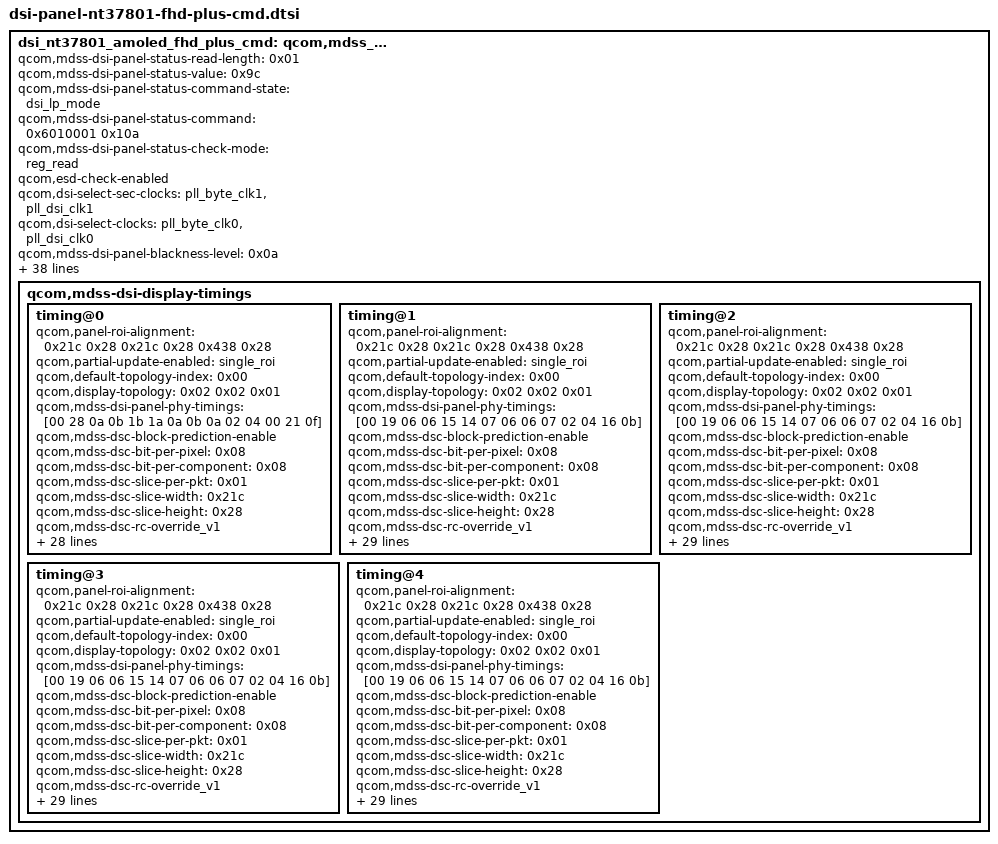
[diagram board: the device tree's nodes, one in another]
// SPDX-License-Identifier: BSD-3-Clause
/*
 * Copyright (c) 2023-2024 Qualcomm Innovation Center, Inc. All rights reserved.
 * Copyright (c) 2025 The LineageOS Project
 */

dsi_nt37801_amoled_fhd_plus_cmd: qcom,mdss_dsi_nt37801_fhd_plus_cmd {
	qcom,mdss-dsi-panel-status-read-length = <0x01>;
	qcom,mdss-dsi-panel-status-value = <0x9c>;
	qcom,mdss-dsi-panel-status-command-state = "dsi_lp_mode";
	qcom,mdss-dsi-panel-status-command = <0x6010001 0x10a>;
	qcom,mdss-dsi-panel-status-check-mode = "reg_read";
	qcom,esd-check-enabled;
	qcom,dsi-select-sec-clocks = "pll_byte_clk1", "pll_dsi_clk1";
	qcom,dsi-select-clocks = "pll_byte_clk0", "pll_dsi_clk0";
	qcom,mdss-dsi-panel-blackness-level = <0x0a>;
	qcom,mdss-dsi-panel-peak-brightness = <0xc65d40>;
	qcom,mdss-dsi-panel-hdr-color-primaries = <0x3b2e 0x3d86 0x85ca 0x3d54 0x2fda 0x8bd8 0x1a5e 0x9f6>;
	qcom,mdss-dsi-panel-hdr-enabled;
	qcom,spr-pack-type = "pentile";
	qcom,mdss-dsi-te-using-te-pin;
	qcom,mdss-dsi-te-check-enable;
	qcom,mdss-dsi-te-dcs-command = <0x01>;
	qcom,mdss-dsi-wr-mem-continue = <0x3c>;
	qcom,mdss-dsi-wr-mem-start = <0x2c>;
	qcom,mdss-dsi-te-pin-select = <0x01>;
	qcom,mdss-dsi-reset-sequence = <0x01 0x0a 0x00 0x0a 0x01 0x0a>;
	qcom,mdss-dsi-mdp-trigger = "none";
	qcom,mdss-dsi-dma-trigger = "trigger_sw";
	qcom,mdss-dsi-lane-3-state;
	qcom,mdss-dsi-lane-2-state;
	qcom,mdss-dsi-lane-1-state;
	qcom,mdss-dsi-lane-0-state;
	qcom,mdss-dsi-bllp-power-mode;
	qcom,mdss-dsi-bllp-eof-power-mode;
	qcom,mdss-dsi-lane-map = "lane_map_0123";
	qcom,mdss-dsi-traffic-mode = "non_burst_sync_event";
	qcom,dsi-sec-phy-num = <0x01>;
	qcom,dsi-sec-ctrl-num = <0x01>;
	qcom,dsi-phy-num = <0x00>;
	qcom,dsi-ctrl-num = <0x00>;
	qcom,mdss-dsi-border-color = <0x00>;
	qcom,mdss-dsi-underflow-color = <0xff>;
	qcom,mdss-dsi-color-order = "rgb_swap_rgb";
	qcom,mdss-dsi-bpp = <0x18>;
	qcom,mdss-dsi-stream = <0x00>;
	qcom,mdss-dsi-virtual-channel-id = <0x00>;
	qcom,mdss-dsi-panel-physical-type = "oled";
	qcom,mdss-dsi-panel-type = "dsi_cmd_mode";
	qcom,mdss-dsi-panel-name = "nt37801 amoled fhd plus cmd mode dsi csot panel with DSC";

	qcom,mdss-dsi-display-timings {

		timing@0 {
			qcom,panel-roi-alignment = <0x21c 0x28 0x21c 0x28 0x438 0x28>;
			qcom,partial-update-enabled = "single_roi";
			qcom,default-topology-index = <0x00>;
			qcom,display-topology = <0x02 0x02 0x01>;
			qcom,mdss-dsi-panel-phy-timings = [00 28 0a 0b 1b 1a 0a 0b 0a 02 04 00 21 0f];
			qcom,mdss-dsc-block-prediction-enable;
			qcom,mdss-dsc-bit-per-pixel = <0x08>;
			qcom,mdss-dsc-bit-per-component = <0x08>;
			qcom,mdss-dsc-slice-per-pkt = <0x01>;
			qcom,mdss-dsc-slice-width = <0x21c>;
			qcom,mdss-dsc-slice-height = <0x28>;
			qcom,mdss-dsc-rc-override_v1;
			qcom,compression-mode = "dsc";
			qcom,mdss-dsi-h-sync-pulse = <0x00>;
			qcom,mdss-dsi-timing-switch-command-state = "dsi_lp_mode";
			qcom,mdss-dsi-off-command-state = "dsi_hs_mode";
			qcom,mdss-dsi-on-command-state = "dsi_lp_mode";
			qcom,mdss-dsi-off-command = [05 01 00 00 14 00 02 28 00 05 01 00 00 78 00 02 10 00];
			qcom,mdss-dsi-on-command = [39 01 00 00 00 00 06 f0 55 aa 52 08 01 39 01 00 00 00 00 02 6f 01 39 01 00 00 00 00 04 c5 0b 0b 0b 39 01 00 00 00 00 05 ff aa 55 a5 80 39 01 00 00 00 00 02 6f 02 39 01 00 00 00 00 02 f5 10 39 01 00 00 00 00 02 6f 1b 39 01 00 00 00 00 02 f4 55 39 01 00 00 00 00 02 6f 18 39 01 00 00 00 00 02 f8 19 39 01 00 00 00 00 02 6f 0f 39 01 00 00 00 00 02 fc 00 39 01 00 00 00 00 05 2a 00 00 04 37 39 01 00 00 00 00 05 2b 00 00 09 5f 39 01 00 00 00 00 02 90 03 39 01 00 00 00 00 13 91 89 28 00 28 c2 00 02 0e 03 dd 00 07 02 77 02 8b 10 f0 39 01 00 00 00 00 05 ff aa 55 a5 81 39 01 00 00 00 00 02 6f 23 39 01 00 00 00 00 15 fb 00 01 00 11 33 33 33 55 57 d0 00 00 44 56 77 78 9a bc dd f0 39 01 00 00 00 00 13 93 89 28 00 28 d2 00 02 25 03 b6 00 07 02 ab 02 8b 10 f0 39 01 00 00 00 00 13 95 89 28 00 28 d2 00 01 c3 02 fc 00 05 02 ab 03 d1 10 f0 39 01 00 00 00 00 02 03 00 39 01 00 00 00 00 02 8f 01 39 01 00 00 00 00 02 6f 06 39 01 00 00 00 00 02 f3 dc 39 01 00 00 00 00 02 26 00 39 01 00 00 00 00 02 35 00 39 01 00 00 00 00 05 3b 00 18 00 10 39 01 00 00 00 00 02 53 20 39 01 00 00 00 00 07 51 07 ff 07 ff 0f ff 39 01 00 00 00 00 02 5a 01 39 01 00 00 00 00 02 5f 00 39 01 00 00 00 00 02 9c 01 05 01 00 00 00 00 01 2c 39 01 00 00 00 00 02 2f 00 05 01 00 00 78 00 01 11 05 01 00 00 14 00 01 29];
			qcom,mdss-dsi-timing-switch-command = [39 01 00 00 00 00 05 2a 00 00 04 37 39 01 00 00 00 00 05 2b 00 00 09 5f 39 01 00 00 00 00 02 8f 01 39 01 00 00 00 00 02 2f 00 39 01 00 00 00 00 02 26 00 39 01 00 00 00 00 06 f0 55 aa 52 08 00 39 01 00 00 00 00 06 c0 54 c0 00 21 43 39 01 00 00 00 00 06 f0 55 aa 52 08 02 39 01 00 00 00 00 02 cc 30 39 01 00 00 00 00 02 ce 01 39 01 00 00 20 00 02 cc 00];
			qcom,mdss-dsi-panel-jitter = <0x04 0x01>;
			qcom,mdss-dsi-v-bottom-border = <0x00>;
			qcom,mdss-dsi-v-top-border = <0x00>;
			qcom,mdss-dsi-h-right-border = <0x00>;
			qcom,mdss-dsi-h-left-border = <0x00>;
			qcom,mdss-dsi-v-pulse-width = <0x02>;
			qcom,mdss-dsi-v-front-porch = <0x14>;
			qcom,mdss-dsi-v-back-porch = <0x12>;
			qcom,mdss-dsi-h-sync-skew = <0x00>;
			qcom,mdss-dsi-h-pulse-width = <0x04>;
			qcom,mdss-dsi-h-back-porch = <0x14>;
			qcom,mdss-dsi-h-front-porch = <0x14>;
			qcom,mdss-dsi-panel-height = <0x960>;
			qcom,mdss-dsi-panel-width = <0x438>;
			qcom,mdss-dsi-panel-framerate = <0x78>;
			cell-index = <0x00>;
		};

		timing@1 {
			qcom,panel-roi-alignment = <0x21c 0x28 0x21c 0x28 0x438 0x28>;
			qcom,partial-update-enabled = "single_roi";
			qcom,default-topology-index = <0x00>;
			qcom,display-topology = <0x02 0x02 0x01>;
			qcom,mdss-dsi-panel-phy-timings = [00 19 06 06 15 14 07 06 06 07 02 04 16 0b];
			qcom,mdss-dsc-block-prediction-enable;
			qcom,mdss-dsc-bit-per-pixel = <0x08>;
			qcom,mdss-dsc-bit-per-component = <0x08>;
			qcom,mdss-dsc-slice-per-pkt = <0x01>;
			qcom,mdss-dsc-slice-width = <0x21c>;
			qcom,mdss-dsc-slice-height = <0x28>;
			qcom,mdss-dsc-rc-override_v1;
			qcom,compression-mode = "dsc";
			qcom,mdss-dsi-h-sync-pulse = <0x00>;
			qcom,mdss-dsi-timing-switch-command-state = "dsi_lp_mode";
			qcom,mdss-dsi-off-command-state = "dsi_hs_mode";
			qcom,mdss-dsi-on-command-state = "dsi_lp_mode";
			qcom,mdss-dsi-off-command = [05 01 00 00 14 00 02 28 00 05 01 00 00 78 00 02 10 00];
			qcom,mdss-dsi-on-command = <0x39010000 0x6f0 0x55aa5208 0x1390100 0x02 0x6f013901 0x00 0x4c50b0b 0xb390100 0x05 0xffaa55a5 0x80390100 0x02 0x6f063901 0x00 0x2f3dc39 0x1000000 0x26f02 0x39010000 0x2f5 0x10390100 0x02 0x6f1b3901 0x00 0x2f45539 0x1000000 0x26f18 0x39010000 0x2f8 0x19390100 0x02 0x6f0f3901 0x00 0x2fc0039 0x1000000 0x52a00 0x43739 0x1000000 0x52b00 0x95f39 0x1000000 0x29003 0x39010000 0x1391 0x89280028 0xc200020e 0x3dd0007 0x277028b 0x10f03901 0x00 0x5ffaa55 0xa5813901 0x00 0x26f2339 0x1000000 0x15fb00 0x1001133 0x33335557 0xd0000044 0x5677789a 0xbcddf039 0x1000000 0x23500 0x39010000 0x53b 0x180010 0x39010000 0x253 0x20390100 0x07 0x5107ff07 0xff0fff39 0x1000000 0x25a01 0x39010000 0x25f 0x390100 0x02 0x9c010501 0x00 0x12c3901 0x00 0x28f0139 0x1000000 0x22f01 0x39010000 0x226 0x1390100 0x06 0xf055aa52 0x8003901 0x00 0x6c054c0 0x244539 0x1000000 0x6f055 0xaa520802 0x39010000 0x2cc 0x30390100 0x02 0xce013901 0x2000 0x2cc0039 0x1000000 0x6f055 0xaa520801 0x39010000 0x5b2 0x5501ff03 0x5010000 0x78000111 0x5010000 0x14000129>;
			qcom,mdss-dsi-timing-switch-command = [39 01 00 00 00 00 05 2a 00 00 04 37 39 01 00 00 00 00 05 2b 00 00 09 5f 39 01 00 00 00 00 02 8f 01 39 01 00 00 00 00 02 2f 01 39 01 00 00 00 00 02 26 01 39 01 00 00 00 00 06 f0 55 aa 52 08 00 39 01 00 00 00 00 06 c0 54 c0 00 24 45 39 01 00 00 00 00 06 f0 55 aa 52 08 02 39 01 00 00 00 00 02 cc 30 39 01 00 00 00 00 02 ce 01 39 01 00 00 20 00 02 cc 00];
			qcom,mdss-dsi-panel-clockrate = <0x2887fa00>;
			qcom,mdss-dsi-panel-jitter = <0x04 0x01>;
			qcom,mdss-dsi-v-bottom-border = <0x00>;
			qcom,mdss-dsi-v-top-border = <0x00>;
			qcom,mdss-dsi-h-right-border = <0x00>;
			qcom,mdss-dsi-h-left-border = <0x00>;
			qcom,mdss-dsi-v-pulse-width = <0x02>;
			qcom,mdss-dsi-v-front-porch = <0x14>;
			qcom,mdss-dsi-v-back-porch = <0x12>;
			qcom,mdss-dsi-h-sync-skew = <0x00>;
			qcom,mdss-dsi-h-pulse-width = <0x04>;
			qcom,mdss-dsi-h-back-porch = <0x14>;
			qcom,mdss-dsi-h-front-porch = <0x14>;
			qcom,mdss-dsi-panel-height = <0x960>;
			qcom,mdss-dsi-panel-width = <0x438>;
			qcom,mdss-dsi-panel-framerate = <0x5a>;
			cell-index = <0x01>;
		};

		timing@2 {
			qcom,panel-roi-alignment = <0x21c 0x28 0x21c 0x28 0x438 0x28>;
			qcom,partial-update-enabled = "single_roi";
			qcom,default-topology-index = <0x00>;
			qcom,display-topology = <0x02 0x02 0x01>;
			qcom,mdss-dsi-panel-phy-timings = [00 19 06 06 15 14 07 06 06 07 02 04 16 0b];
			qcom,mdss-dsc-block-prediction-enable;
			qcom,mdss-dsc-bit-per-pixel = <0x08>;
			qcom,mdss-dsc-bit-per-component = <0x08>;
			qcom,mdss-dsc-slice-per-pkt = <0x01>;
			qcom,mdss-dsc-slice-width = <0x21c>;
			qcom,mdss-dsc-slice-height = <0x28>;
			qcom,mdss-dsc-rc-override_v1;
			qcom,compression-mode = "dsc";
			qcom,mdss-dsi-h-sync-pulse = <0x00>;
			qcom,mdss-dsi-timing-switch-command-state = "dsi_lp_mode";
			qcom,mdss-dsi-off-command-state = "dsi_hs_mode";
			qcom,mdss-dsi-on-command-state = "dsi_lp_mode";
			qcom,mdss-dsi-off-command = [05 01 00 00 14 00 02 28 00 05 01 00 00 78 00 02 10 00];
			qcom,mdss-dsi-on-command = [39 01 00 00 00 00 06 f0 55 aa 52 08 01 39 01 00 00 00 00 02 6f 01 39 01 00 00 00 00 04 c5 0b 0b 0b 39 01 00 00 00 00 05 ff aa 55 a5 80 39 01 00 00 00 00 02 6f 02 39 01 00 00 00 00 02 f5 10 39 01 00 00 00 00 02 6f 1b 39 01 00 00 00 00 02 f4 55 39 01 00 00 00 00 02 6f 18 39 01 00 00 00 00 02 f8 19 39 01 00 00 00 00 02 6f 0f 39 01 00 00 00 00 02 fc 00 39 01 00 00 00 00 05 2a 00 00 04 37 39 01 00 00 00 00 05 2b 00 00 09 5f 39 01 00 00 00 00 02 90 03 39 01 00 00 00 00 13 91 89 28 00 28 c2 00 02 0e 03 dd 00 07 02 77 02 8b 10 f0 39 01 00 00 00 00 05 ff aa 55 a5 81 39 01 00 00 00 00 02 6f 23 39 01 00 00 00 00 15 fb 00 01 00 11 33 33 33 55 57 d0 00 00 44 56 77 78 9a bc dd f0 39 01 00 00 00 00 02 6f 06 39 01 00 00 00 00 02 f3 dc 39 01 00 00 00 00 02 26 00 39 01 00 00 00 00 02 35 00 39 01 00 00 00 00 05 3b 00 18 00 10 39 01 00 00 00 00 02 53 20 39 01 00 00 00 00 07 51 07 ff 07 ff 0f ff 39 01 00 00 00 00 02 5a 01 39 01 00 00 00 00 02 5f 00 39 01 00 00 00 00 02 9c 01 05 01 00 00 00 00 01 2c 39 01 00 00 00 00 02 8f 01 39 01 00 00 00 00 02 2f 00 39 01 00 00 00 00 02 26 01 39 01 00 00 00 00 02 5a 01 39 01 00 00 00 00 02 2f 30 39 01 00 00 00 00 06 f0 55 aa 52 08 00 39 01 00 00 00 00 02 6f 1c 39 01 00 00 00 00 09 ba 91 01 01 00 01 01 01 00 39 01 00 00 00 00 06 f0 55 aa 52 08 00 39 01 00 00 00 00 06 c0 54 c0 00 21 43 39 01 00 00 00 00 06 f0 55 aa 52 08 02 39 01 00 00 00 00 02 cc 30 39 01 00 00 00 00 02 ce 01 39 01 00 00 20 00 02 cc 00 39 01 00 00 00 00 06 f0 55 aa 52 08 01 39 01 00 00 00 00 05 b2 55 01 ff 03 05 01 00 00 78 00 01 11 05 01 00 00 14 00 01 29];
			qcom,mdss-dsi-timing-switch-command = [39 01 00 00 00 00 05 2a 00 00 04 37 39 01 00 00 00 00 05 2b 00 00 09 5f 39 01 00 00 00 00 02 8f 01 39 01 00 00 00 00 02 2f 00 39 01 00 00 00 00 02 26 01 39 01 00 00 00 00 02 5a 01 39 01 00 00 00 00 02 2f 30 39 01 00 00 00 00 06 f0 55 aa 52 08 00 39 01 00 00 00 00 02 6f 1c 39 01 00 00 00 00 09 ba 91 01 01 00 01 01 01 00 39 01 00 00 00 00 06 f0 55 aa 52 08 00 39 01 00 00 00 00 06 c0 54 c0 00 21 43 39 01 00 00 00 00 06 f0 55 aa 52 08 02 39 01 00 00 00 00 02 cc 30 39 01 00 00 00 00 02 ce 01 39 01 00 00 20 00 02 cc 00];
			qcom,mdss-dsi-panel-clockrate = <0x2887fa00>;
			qcom,mdss-dsi-panel-jitter = <0x04 0x01>;
			qcom,mdss-dsi-v-bottom-border = <0x00>;
			qcom,mdss-dsi-v-top-border = <0x00>;
			qcom,mdss-dsi-h-right-border = <0x00>;
			qcom,mdss-dsi-h-left-border = <0x00>;
			qcom,mdss-dsi-v-pulse-width = <0x02>;
			qcom,mdss-dsi-v-front-porch = <0x14>;
			qcom,mdss-dsi-v-back-porch = <0x12>;
			qcom,mdss-dsi-h-sync-skew = <0x00>;
			qcom,mdss-dsi-h-pulse-width = <0x04>;
			qcom,mdss-dsi-h-back-porch = <0x14>;
			qcom,mdss-dsi-h-front-porch = <0x14>;
			qcom,mdss-dsi-panel-height = <0x960>;
			qcom,mdss-dsi-panel-width = <0x438>;
			qcom,mdss-dsi-panel-framerate = <0x3c>;
			cell-index = <0x02>;
		};

		timing@3 {
			qcom,panel-roi-alignment = <0x21c 0x28 0x21c 0x28 0x438 0x28>;
			qcom,partial-update-enabled = "single_roi";
			qcom,default-topology-index = <0x00>;
			qcom,display-topology = <0x02 0x02 0x01>;
			qcom,mdss-dsi-panel-phy-timings = [00 19 06 06 15 14 07 06 06 07 02 04 16 0b];
			qcom,mdss-dsc-block-prediction-enable;
			qcom,mdss-dsc-bit-per-pixel = <0x08>;
			qcom,mdss-dsc-bit-per-component = <0x08>;
			qcom,mdss-dsc-slice-per-pkt = <0x01>;
			qcom,mdss-dsc-slice-width = <0x21c>;
			qcom,mdss-dsc-slice-height = <0x28>;
			qcom,mdss-dsc-rc-override_v1;
			qcom,compression-mode = "dsc";
			qcom,mdss-dsi-h-sync-pulse = <0x00>;
			qcom,mdss-dsi-timing-switch-command-state = "dsi_lp_mode";
			qcom,mdss-dsi-off-command-state = "dsi_hs_mode";
			qcom,mdss-dsi-on-command-state = "dsi_lp_mode";
			qcom,mdss-dsi-off-command = [05 01 00 00 14 00 02 28 00 05 01 00 00 78 00 02 10 00];
			qcom,mdss-dsi-on-command = [39 01 00 00 00 00 06 f0 55 aa 52 08 01 39 01 00 00 00 00 02 6f 01 39 01 00 00 00 00 04 c5 0b 0b 0b 39 01 00 00 00 00 05 ff aa 55 a5 80 39 01 00 00 00 00 02 6f 02 39 01 00 00 00 00 02 f5 10 39 01 00 00 00 00 02 6f 1b 39 01 00 00 00 00 02 f4 55 39 01 00 00 00 00 02 6f 18 39 01 00 00 00 00 02 f8 19 39 01 00 00 00 00 02 6f 0f 39 01 00 00 00 00 02 fc 00 39 01 00 00 00 00 05 2a 00 00 04 37 39 01 00 00 00 00 05 2b 00 00 09 5f 39 01 00 00 00 00 02 90 03 39 01 00 00 00 00 13 91 89 28 00 28 c2 00 02 0e 03 dd 00 07 02 77 02 8b 10 f0 39 01 00 00 00 00 05 ff aa 55 a5 81 39 01 00 00 00 00 02 6f 23 39 01 00 00 00 00 15 fb 00 01 00 11 33 33 33 55 57 d0 00 00 44 56 77 78 9a bc dd f0 39 01 00 00 00 00 02 6f 06 39 01 00 00 00 00 02 f3 dc 39 01 00 00 00 00 02 26 00 39 01 00 00 00 00 02 35 00 39 01 00 00 00 00 05 3b 00 18 00 10 39 01 00 00 00 00 02 53 20 39 01 00 00 00 00 07 51 07 ff 07 ff 0f ff 39 01 00 00 00 00 02 5a 01 39 01 00 00 00 00 02 5f 00 39 01 00 00 00 00 02 9c 01 05 01 00 00 00 00 01 2c 39 01 00 00 00 00 02 8f 01 39 01 00 00 00 00 02 2f 00 39 01 00 00 00 00 02 26 01 39 01 00 00 00 00 02 5a 01 39 01 00 00 00 00 02 2f 30 39 01 00 00 00 00 06 f0 55 aa 52 08 00 39 01 00 00 00 00 02 6f 1c 39 01 00 00 00 00 09 ba 91 02 02 00 01 02 02 00 39 01 00 00 00 00 06 f0 55 aa 52 08 00 39 01 00 00 00 00 06 c0 54 c0 00 21 43 39 01 00 00 00 00 06 f0 55 aa 52 08 02 39 01 00 00 00 00 02 cc 30 39 01 00 00 00 00 02 ce 01 39 01 00 00 20 00 02 cc 00 39 01 00 00 00 00 06 f0 55 aa 52 08 01 39 01 00 00 00 00 05 b2 55 01 ff 03 05 01 00 00 78 00 01 11 05 01 00 00 14 00 01 29];
			qcom,mdss-dsi-timing-switch-command = [39 01 00 00 00 00 05 2a 00 00 04 37 39 01 00 00 00 00 05 2b 00 00 09 5f 39 01 00 00 00 00 02 8f 01 39 01 00 00 00 00 02 2f 00 39 01 00 00 00 00 02 26 01 39 01 00 00 00 00 02 5a 01 39 01 00 00 00 00 02 2f 30 39 01 00 00 00 00 06 f0 55 aa 52 08 00 39 01 00 00 00 00 02 6f 1c 39 01 00 00 00 00 09 ba 91 02 02 00 01 02 02 00 39 01 00 00 00 00 06 f0 55 aa 52 08 00 39 01 00 00 00 00 06 c0 54 c0 00 21 43 39 01 00 00 00 00 06 f0 55 aa 52 08 02 39 01 00 00 00 00 02 cc 30 39 01 00 00 00 00 02 ce 01 39 01 00 00 20 00 02 cc 00];
			qcom,mdss-dsi-panel-clockrate = <0x2887fa00>;
			qcom,mdss-dsi-panel-jitter = <0x04 0x01>;
			qcom,mdss-dsi-v-bottom-border = <0x00>;
			qcom,mdss-dsi-v-top-border = <0x00>;
			qcom,mdss-dsi-h-right-border = <0x00>;
			qcom,mdss-dsi-h-left-border = <0x00>;
			qcom,mdss-dsi-v-pulse-width = <0x02>;
			qcom,mdss-dsi-v-front-porch = <0x14>;
			qcom,mdss-dsi-v-back-porch = <0x12>;
			qcom,mdss-dsi-h-sync-skew = <0x00>;
			qcom,mdss-dsi-h-pulse-width = <0x04>;
			qcom,mdss-dsi-h-back-porch = <0x14>;
			qcom,mdss-dsi-h-front-porch = <0x14>;
			qcom,mdss-dsi-panel-height = <0x960>;
			qcom,mdss-dsi-panel-width = <0x438>;
			qcom,mdss-dsi-panel-framerate = <0x28>;
			cell-index = <0x03>;
		};

		timing@4 {
			qcom,panel-roi-alignment = <0x21c 0x28 0x21c 0x28 0x438 0x28>;
			qcom,partial-update-enabled = "single_roi";
			qcom,default-topology-index = <0x00>;
			qcom,display-topology = <0x02 0x02 0x01>;
			qcom,mdss-dsi-panel-phy-timings = [00 19 06 06 15 14 07 06 06 07 02 04 16 0b];
			qcom,mdss-dsc-block-prediction-enable;
			qcom,mdss-dsc-bit-per-pixel = <0x08>;
			qcom,mdss-dsc-bit-per-component = <0x08>;
			qcom,mdss-dsc-slice-per-pkt = <0x01>;
			qcom,mdss-dsc-slice-width = <0x21c>;
			qcom,mdss-dsc-slice-height = <0x28>;
			qcom,mdss-dsc-rc-override_v1;
			qcom,compression-mode = "dsc";
			qcom,mdss-dsi-h-sync-pulse = <0x00>;
			qcom,mdss-dsi-timing-switch-command-state = "dsi_lp_mode";
			qcom,mdss-dsi-off-command-state = "dsi_hs_mode";
			qcom,mdss-dsi-on-command-state = "dsi_lp_mode";
			qcom,mdss-dsi-off-command = [05 01 00 00 14 00 02 28 00 05 01 00 00 78 00 02 10 00];
			qcom,mdss-dsi-on-command = [39 01 00 00 00 00 06 f0 55 aa 52 08 01 39 01 00 00 00 00 02 6f 01 39 01 00 00 00 00 04 c5 0b 0b 0b 39 01 00 00 00 00 05 ff aa 55 a5 80 39 01 00 00 00 00 02 6f 02 39 01 00 00 00 00 02 f5 10 39 01 00 00 00 00 02 6f 1b 39 01 00 00 00 00 02 f4 55 39 01 00 00 00 00 02 6f 18 39 01 00 00 00 00 02 f8 19 39 01 00 00 00 00 02 6f 0f 39 01 00 00 00 00 02 fc 00 39 01 00 00 00 00 05 2a 00 00 04 37 39 01 00 00 00 00 05 2b 00 00 09 5f 39 01 00 00 00 00 02 90 03 39 01 00 00 00 00 13 91 89 28 00 28 c2 00 02 0e 03 dd 00 07 02 77 02 8b 10 f0 39 01 00 00 00 00 05 ff aa 55 a5 81 39 01 00 00 00 00 02 6f 23 39 01 00 00 00 00 15 fb 00 01 00 11 33 33 33 55 57 d0 00 00 44 56 77 78 9a bc dd f0 39 01 00 00 00 00 02 6f 06 39 01 00 00 00 00 02 f3 dc 39 01 00 00 00 00 02 26 00 39 01 00 00 00 00 02 35 00 39 01 00 00 00 00 05 3b 00 18 00 10 39 01 00 00 00 00 02 53 20 39 01 00 00 00 00 07 51 07 ff 07 ff 0f ff 39 01 00 00 00 00 02 5a 01 39 01 00 00 00 00 02 5f 00 39 01 00 00 00 00 02 9c 01 05 01 00 00 00 00 01 2c 39 01 00 00 00 00 02 8f 01 39 01 00 00 00 00 02 2f 00 39 01 00 00 00 00 02 26 01 39 01 00 00 00 00 02 5a 01 39 01 00 00 00 00 02 2f 30 39 01 00 00 00 00 06 f0 55 aa 52 08 00 39 01 00 00 00 00 02 6f 1c 39 01 00 00 00 00 09 ba 91 03 03 00 01 03 03 00 39 01 00 00 00 00 06 f0 55 aa 52 08 00 39 01 00 00 00 00 06 c0 54 c0 00 21 43 39 01 00 00 00 00 06 f0 55 aa 52 08 02 39 01 00 00 00 00 02 cc 30 39 01 00 00 00 00 02 ce 01 39 01 00 00 20 00 02 cc 00 39 01 00 00 00 00 06 f0 55 aa 52 08 01 39 01 00 00 00 00 05 b2 55 01 ff 03 05 01 00 00 78 00 01 11 05 01 00 00 14 00 01 29];
			qcom,mdss-dsi-timing-switch-command = [39 01 00 00 00 00 05 2a 00 00 04 37 39 01 00 00 00 00 05 2b 00 00 09 5f 39 01 00 00 00 00 02 8f 01 39 01 00 00 00 00 02 2f 00 39 01 00 00 00 00 02 26 01 39 01 00 00 00 00 02 5a 01 39 01 00 00 00 00 02 2f 30 39 01 00 00 00 00 06 f0 55 aa 52 08 00 39 01 00 00 00 00 02 6f 1c 39 01 00 00 00 00 09 ba 91 03 03 00 01 03 03 00 39 01 00 00 00 00 06 f0 55 aa 52 08 00 39 01 00 00 00 00 06 c0 54 c0 00 21 43 39 01 00 00 00 00 06 f0 55 aa 52 08 02 39 01 00 00 00 00 02 cc 30 39 01 00 00 00 00 02 ce 01 39 01 00 00 20 00 02 cc 00];
			qcom,mdss-dsi-panel-clockrate = <0x2887fa00>;
			qcom,mdss-dsi-panel-jitter = <0x04 0x01>;
			qcom,mdss-dsi-v-bottom-border = <0x00>;
			qcom,mdss-dsi-v-top-border = <0x00>;
			qcom,mdss-dsi-h-right-border = <0x00>;
			qcom,mdss-dsi-h-left-border = <0x00>;
			qcom,mdss-dsi-v-pulse-width = <0x02>;
			qcom,mdss-dsi-v-front-porch = <0x14>;
			qcom,mdss-dsi-v-back-porch = <0x12>;
			qcom,mdss-dsi-h-sync-skew = <0x00>;
			qcom,mdss-dsi-h-pulse-width = <0x04>;
			qcom,mdss-dsi-h-back-porch = <0x14>;
			qcom,mdss-dsi-h-front-porch = <0x14>;
			qcom,mdss-dsi-panel-height = <0x960>;
			qcom,mdss-dsi-panel-width = <0x438>;
			qcom,mdss-dsi-panel-framerate = <0x1e>;
			cell-index = <0x04>;
		};
	};
};
